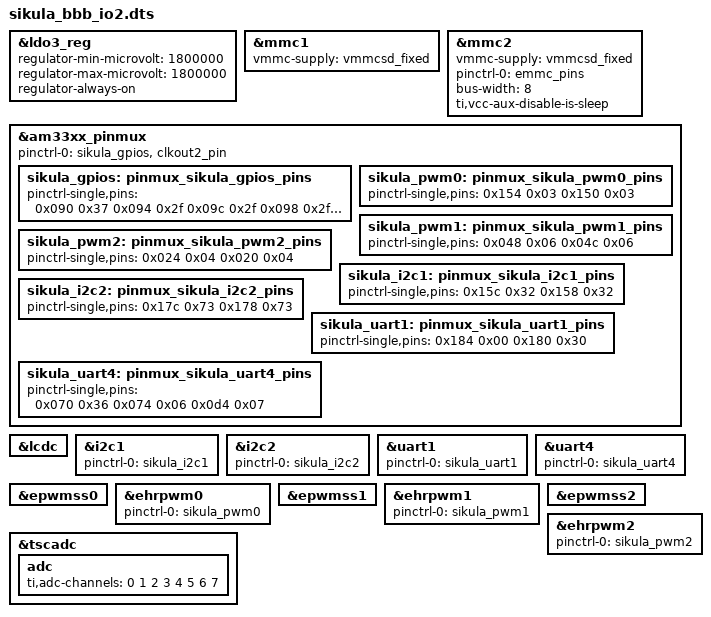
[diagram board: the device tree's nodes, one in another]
/dts-v1/;

#include "am33xx.dtsi"
#include "am335x-bone-common.dtsi"

&ldo3_reg {
	regulator-min-microvolt = <1800000>;
	regulator-max-microvolt = <1800000>;
	regulator-always-on;
};

&mmc1 {
	vmmc-supply = <&vmmcsd_fixed>;
};

&mmc2 {
	vmmc-supply = <&vmmcsd_fixed>;
	pinctrl-names = "default";
	pinctrl-0 = <&emmc_pins>;
	bus-width = <8>;
	status = "okay";
	ti,vcc-aux-disable-is-sleep;
};

&am33xx_pinmux {
	pinctrl-names = "default";
	pinctrl-0 = <&sikula_gpios &clkout2_pin>;

	sikula_gpios: pinmux_sikula_gpios_pins {
		pinctrl-single,pins = <
			0x090 0x37 /* Jack IN */
			0x094 0x2f /* CPT4 IO */
			0x09c 0x2f /* CPT5 IO */
			0x098 0x2f /* CPT6 IO */
			0x028 0x07 /* MOTOR_IND3 OUT */
			0x03c 0x07 /* MOTOR_IND4 OUT */
			0x038 0x07 /* MOTOR_EN OUT */
			0x02c 0x07 /* MOTOR_ING2 OUT */
			0x08c 0x07 /* MOTOR_ING1 OUT */
			0x07c 0x07 /* TRSL_BIDI_OE123 OUT */
			0x0e0 0x07 /* LED0 OUT */
			0x0e8 0x07 /* LED1 OUT */
			0x0e4 0x07 /* LED2 OUT */
			0x0ec 0x07 /* LED3 OUT */
			0x0d8 0x37 /* BP9 IN */
			0x0dc 0x37 /* BP8 IN */
			0x0cc 0x07 /* MOS11 OUT */
			0x0d0 0x37 /* BP7 IN */
			0x0c8 0x07 /* MOS12 OUT */
			0x0c0 0x37 /* BP6 IN */
			0x0c4 0x37 /* BP5 IN */
			0x0b8 0x07 /* MOS21 OUT */
			0x0bc 0x07 /* MOS22 OUT */
			0x0b0 0x07 /* LED4 OUT */
			0x0b4 0x07 /* LED5 OUT */
			0x0a8 0x07 /* LED6 OUT */
			0x0ac 0x07 /* LED7 OUT */
			0x0a0 0x07 /* MOS31 OUT */
			0x0a4 0x07 /* MOS32 OUT */
			0x078 0x07 /* AX12_EN_REG OUT */
			0x040 0x2f /* CPT5V5 IO */
			0x044 0x37 /* SERIAL2_DIR2 IN */
			0x19c 0x37 /* BP4 IN */
			0x194 0x37 /* BP3 IN */
			0x198 0x37 /* BP2 IN */
			0x190 0x37 /* BP1 IN */
			0x1a0 0x2f /* SERIAL2_EN2 OUT (1/2) */
			0x164 0x07 /* SERIAL2_EN2 OUT (2/2) */
		>;
	};
	sikula_pwm0: pinmux_sikula_pwm0_pins {
		pinctrl-single,pins = <
			0x154 0x03 /* SERVO3 */
			0x150 0x03 /* SERVO4 */
		>;
	};
	sikula_pwm1: pinmux_sikula_pwm1_pins {
		pinctrl-single,pins = <
			0x048 0x06 /* SERVO1 */
			0x04c 0x06 /* SERVO2 */
		>;
	};
	sikula_pwm2: pinmux_sikula_pwm2_pins {
		pinctrl-single,pins = <
			0x024 0x04 /* MOTOR PWM R */
			0x020 0x04 /* MOTOR PWM L */
		>;
	};
	sikula_i2c1: pinmux_sikula_i2c1_pins {
		pinctrl-single,pins = <
			0x15c 0x32 /* I2C1_SCL */
			0x158 0x32 /* I2C1_SDA */
		>;
	};
	sikula_i2c2: pinmux_sikula_i2c2_pins {
		pinctrl-single,pins = <
			0x17c 0x73 /* I2C2_SCL */
			0x178 0x73 /* I2C2_SDA */
		>;
	};
	sikula_uart1: pinmux_sikula_uart1_pins {
		pinctrl-single,pins = <
			0x184 0x00 /* SERIAL2_TXD2 */
			0x180 0x30 /* SERIAL2_RXD2 */
		>;
	};
	sikula_uart4: pinmux_sikula_uart4_pins {
		pinctrl-single,pins = <
			0x070 0x36 /* AX12_RX */
			0x074 0x06 /* AX12_TX */
			0x0d4 0x07 /* AX12_DIRECTION */
		>;
	};
};

&lcdc {
	status = "okay";
};

&i2c1 {
	status = "okay";
	pinctrl-names = "default";
	pinctrl-0 = <&sikula_i2c1>;
};

&i2c2 {
	status = "okay";
	pinctrl-names = "default";
	pinctrl-0 = <&sikula_i2c2>;
};

&uart1 {
	status = "okay";
	pinctrl-names = "default";
	pinctrl-0 = <&sikula_uart1>;
};

&uart4 {
	status = "okay";
	pinctrl-names = "default";
	pinctrl-0 = <&sikula_uart4>;
/*
	rs485-rts-delay = <0 0>;
	rs485-rts-active-high;
	rs485-gpio = <&gpio0 7 0>;
	linux,rs485-enabled-at-boot-time;
*/
};

&epwmss0 {
	status = "okay";
};

&ehrpwm0 {
	status = "okay";
	pinctrl-names = "default";
	pinctrl-0 = <&sikula_pwm0>;
};

&epwmss1 {
	status = "okay";
};

&ehrpwm1 {
	status = "okay";
	pinctrl-names = "default";
	pinctrl-0 = <&sikula_pwm1>;
};

&epwmss2 {
	status = "okay";
};

&ehrpwm2 {
	status = "okay";
	pinctrl-names = "default";
	pinctrl-0 = <&sikula_pwm2>;
};

&tscadc {
	status = "okay";
	adc {
		ti,adc-channels = <0 1 2 3 4 5 6 7>;
	};
};
